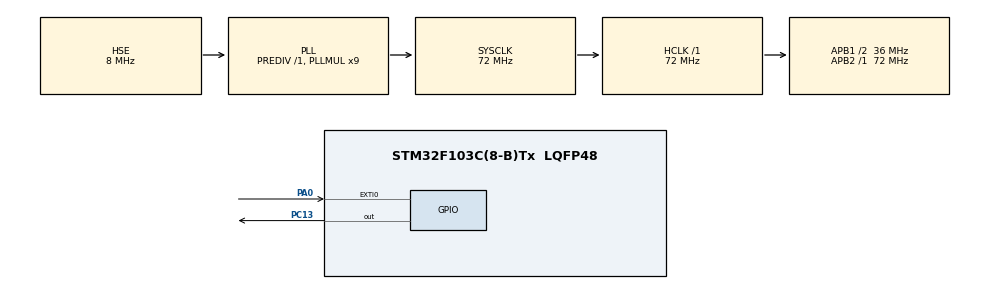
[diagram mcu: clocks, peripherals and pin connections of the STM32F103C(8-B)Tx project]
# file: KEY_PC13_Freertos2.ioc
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FREERTOS.Queues01=KeyQueue,8,uint8_t,0,Dynamic,NULL,NULL
FREERTOS.Tasks01=KeyTask,16,128,StartKeyTask,Default,NULL,Dynamic,NULL,NULL;LedTask,24,128,StartLedTask,Default,NULL,Dynamic,NULL,NULL
Mcu.Family=STM32F1
Mcu.Name=STM32F103C(8-B)Tx
Mcu.Package=LQFP48
NVIC.EXTI0_IRQn=true\:5\:0\:false\:false\:true\:true\:true\:true\:true
NVIC.PriorityGroup=NVIC_PRIORITYGROUP_4
NVIC.TIM4_IRQn=true\:15\:0\:false\:false\:true\:false\:false\:true\:true
NVIC.TimeBase=TIM4_IRQn
NVIC.TimeBaseIP=TIM4
PA0-WKUP.GPIO_ModeDefaultEXTI=GPIO_MODE_IT_FALLING
PA0-WKUP.GPIO_PuPd=GPIO_PULLUP
PA0-WKUP.Signal=GPXTI0
PA13.Mode=Serial_Wire
PA13.Signal=SYS_JTMS-SWDIO
PA14.Mode=Serial_Wire
PA14.Signal=SYS_JTCK-SWCLK
PC13-TAMPER-RTC.PinState=GPIO_PIN_SET
PC13-TAMPER-RTC.Signal=GPIO_Output
PD0-OSC_IN.Mode=HSE-External-Oscillator
PD0-OSC_IN.Signal=RCC_OSC_IN
PD1-OSC_OUT.Mode=HSE-External-Oscillator
PD1-OSC_OUT.Signal=RCC_OSC_OUT
ProjectManager.HeapSize=0x200
ProjectManager.StackSize=0x400
ProjectManager.TargetToolchain=MDK-ARM V5.32
RCC.AHBFreq_Value=72000000
RCC.APB1CLKDivider=RCC_HCLK_DIV2
RCC.APB1Freq_Value=36000000
RCC.APB1TimFreq_Value=72000000
RCC.APB2Freq_Value=72000000
RCC.APB2TimFreq_Value=72000000
RCC.EnbaleCSS=true
RCC.HCLKFreq_Value=72000000
RCC.PLLMUL=RCC_PLL_MUL9
RCC.PLLSourceVirtual=RCC_PLLSOURCE_HSE
RCC.SYSCLKFreq_VALUE=72000000
RCC.SYSCLKSource=RCC_SYSCLKSOURCE_PLLCLK
RCC.USBFreq_Value=72000000
VP_FREERTOS_VS_CMSIS_V2.Mode=CMSIS_V2
VP_SYS_VS_tim4.Mode=TIM4
board=custom

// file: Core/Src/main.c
/* USER CODE BEGIN Header */
/**
  ******************************************************************************
  * @file           : main.c
  * @brief          : Main program body
  ******************************************************************************
  * @attention
  *
  * Copyright (c) 2025 STMicroelectronics.
  * All rights reserved.
  *
  * This software is licensed under terms that can be found in the LICENSE file
  * in the root directory of this software component.
  * If no LICENSE file comes with this software, it is provided AS-IS.
  *
  ******************************************************************************
  */
/* USER CODE END Header */
#include "main.h"
#include "cmsis_os.h"
#include "gpio.h"

void SystemClock_Config(void);
void MX_FREERTOS_Init(void);

int main(void)
{

  /* MCU Configuration--------------------------------------------------------*/

  /* Reset of all peripherals, Initializes the Flash interface and the Systick. */
  HAL_Init();

  /* Configure the system clock */
  SystemClock_Config();

  /* Initialize all configured peripherals */
  MX_GPIO_Init();

  /* Init scheduler */
  osKernelInitialize();

  /* Call init function for freertos objects (in cmsis_os2.c) */
  MX_FREERTOS_Init();

  /* Start scheduler */
  osKernelStart();

  /* We should never get here as control is now taken by the scheduler */

  /* Infinite loop */
  while (1)
  {

  }
}

void SystemClock_Config(void)
{
  RCC_OscInitTypeDef RCC_OscInitStruct = {0};
  RCC_ClkInitTypeDef RCC_ClkInitStruct = {0};

  /** Initializes the RCC Oscillators according to the specified parameters
  * in the RCC_OscInitTypeDef structure.
  */
  RCC_OscInitStruct.OscillatorType = RCC_OSCILLATORTYPE_HSE;
  RCC_OscInitStruct.HSEState = RCC_HSE_ON;
  RCC_OscInitStruct.HSEPredivValue = RCC_HSE_PREDIV_DIV1;
  RCC_OscInitStruct.HSIState = RCC_HSI_ON;
  RCC_OscInitStruct.PLL.PLLState = RCC_PLL_ON;
  RCC_OscInitStruct.PLL.PLLSource = RCC_PLLSOURCE_HSE;
  RCC_OscInitStruct.PLL.PLLMUL = RCC_PLL_MUL9;
  if (HAL_RCC_OscConfig(&RCC_OscInitStruct) != HAL_OK)
  {
    Error_Handler();
  }

  /** Initializes the CPU, AHB and APB buses clocks
  */
  RCC_ClkInitStruct.ClockType = RCC_CLOCKTYPE_HCLK|RCC_CLOCKTYPE_SYSCLK
                              |RCC_CLOCKTYPE_PCLK1|RCC_CLOCKTYPE_PCLK2;
  RCC_ClkInitStruct.SYSCLKSource = RCC_SYSCLKSOURCE_PLLCLK;
  RCC_ClkInitStruct.AHBCLKDivider = RCC_SYSCLK_DIV1;
  RCC_ClkInitStruct.APB1CLKDivider = RCC_HCLK_DIV2;
  RCC_ClkInitStruct.APB2CLKDivider = RCC_HCLK_DIV1;

  if (HAL_RCC_ClockConfig(&RCC_ClkInitStruct, FLASH_LATENCY_2) != HAL_OK)
  {
    Error_Handler();
  }

  /** Enables the Clock Security System
  */
  HAL_RCC_EnableCSS();
}

void HAL_TIM_PeriodElapsedCallback(TIM_HandleTypeDef *htim)
{
  if (htim->Instance == TIM4)
  {
    HAL_IncTick();
  }
}

void Error_Handler(void)
{
  __disable_irq();
  while (1)
  {
  }
}

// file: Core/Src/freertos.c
/* USER CODE BEGIN Header */
/**
  ******************************************************************************
  * File Name          : freertos.c
  * Description        : Code for freertos applications
  ******************************************************************************
  * @attention
  *
  * Copyright (c) 2025 STMicroelectronics.
  * All rights reserved.
  *
  * This software is licensed under terms that can be found in the LICENSE file
  * in the root directory of this software component.
  * If no LICENSE file comes with this software, it is provided AS-IS.
  *
  ******************************************************************************
  */
/* USER CODE END Header */

#include "FreeRTOS.h"
#include "task.h"
#include "main.h"
#include "cmsis_os.h"

/* Definitions for KeyTask */
osThreadId_t KeyTaskHandle;
const osThreadAttr_t KeyTask_attributes = {
  .name = "KeyTask",
  .stack_size = 128 * 4,
  .priority = (osPriority_t) osPriorityBelowNormal,
};
/* Definitions for LedTask */
osThreadId_t LedTaskHandle;
const osThreadAttr_t LedTask_attributes = {
  .name = "LedTask",
  .stack_size = 128 * 4,
  .priority = (osPriority_t) osPriorityNormal,
};
/* Definitions for KeyQueue */
osMessageQueueId_t KeyQueueHandle;
const osMessageQueueAttr_t KeyQueue_attributes = {
  .name = "KeyQueue"
};

void StartKeyTask(void *argument);
void StartLedTask(void *argument);

void MX_FREERTOS_Init(void); /* (MISRA C 2004 rule 8.1) */

void MX_FREERTOS_Init(void) {

  /* Create the queue(s) */
  /* creation of KeyQueue */
  KeyQueueHandle = osMessageQueueNew (8, sizeof(uint8_t), &KeyQueue_attributes);

  /* Create the thread(s) */
  /* creation of KeyTask */
  KeyTaskHandle = osThreadNew(StartKeyTask, NULL, &KeyTask_attributes);

  /* creation of LedTask */
  LedTaskHandle = osThreadNew(StartLedTask, NULL, &LedTask_attributes);

}

void StartKeyTask(void *argument)
{
  /* USER CODE BEGIN StartKeyTask */
  /* Infinite loop */
  for(;;)
  {
    if (osMessageQueueGetCount(KeyQueueHandle) > 0) // 检查队列中是否有按键消息
    {
      uint8_t keyState;
      if (osMessageQueueGet(KeyQueueHandle, &keyState, NULL, 0) == osOK) // 从队列中获取按键状态
      {
        // 这里可以添加按键处理逻辑，例如去抖动等
      }
    }
    osDelay(1);
  }
  /* USER CODE END StartKeyTask */
}

void StartLedTask(void *argument)
{
  /* USER CODE BEGIN StartLedTask */
  /* Infinite loop */
  for(;;)
  {
    if (osMessageQueueGetCount(KeyQueueHandle) > 0) // 检查队列中是否有按键消息
    {
      uint8_t keyState;
      if (osMessageQueueGet(KeyQueueHandle, &keyState, NULL, 0) == osOK) // 从队列中获取按键状态
      {
        if (keyState == 1) // 如果按键按下
        {
          HAL_GPIO_TogglePin(GPIOC, GPIO_PIN_13); // 切换LED状态
        }
      }
    }
    osDelay(1);
  }
  /* USER CODE END StartLedTask */
}
